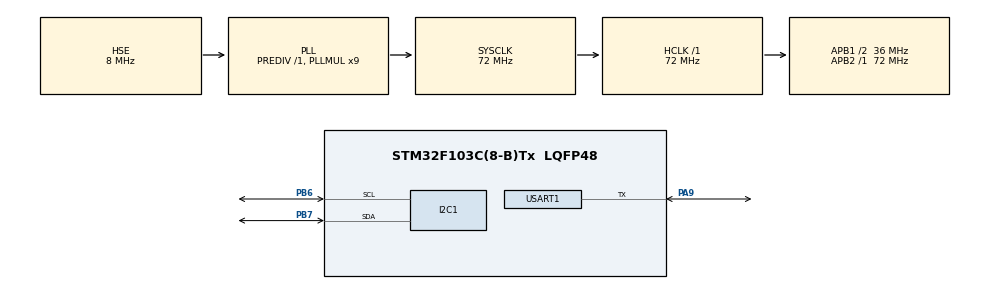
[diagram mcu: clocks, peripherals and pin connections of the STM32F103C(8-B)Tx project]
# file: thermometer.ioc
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Dma.Request0=USART1_RX
Dma.Request1=USART1_TX
Dma.USART1_RX.0.Direction=DMA_PERIPH_TO_MEMORY
Dma.USART1_RX.0.Instance=DMA1_Channel5
Dma.USART1_RX.0.MemDataAlignment=DMA_MDATAALIGN_BYTE
Dma.USART1_RX.0.MemInc=DMA_MINC_ENABLE
Dma.USART1_RX.0.Mode=DMA_NORMAL
Dma.USART1_RX.0.PeriphDataAlignment=DMA_PDATAALIGN_BYTE
Dma.USART1_RX.0.PeriphInc=DMA_PINC_DISABLE
Dma.USART1_RX.0.Priority=DMA_PRIORITY_LOW
Dma.USART1_TX.1.Direction=DMA_MEMORY_TO_PERIPH
Dma.USART1_TX.1.Instance=DMA1_Channel4
Dma.USART1_TX.1.MemDataAlignment=DMA_MDATAALIGN_BYTE
Dma.USART1_TX.1.MemInc=DMA_MINC_ENABLE
Dma.USART1_TX.1.Mode=DMA_NORMAL
Dma.USART1_TX.1.PeriphDataAlignment=DMA_PDATAALIGN_BYTE
Dma.USART1_TX.1.PeriphInc=DMA_PINC_DISABLE
Dma.USART1_TX.1.Priority=DMA_PRIORITY_LOW
Mcu.Family=STM32F1
Mcu.Name=STM32F103C(8-B)Tx
Mcu.Package=LQFP48
NVIC.DMA1_Channel4_IRQn=true\:15\:0\:true\:false\:true\:false\:true\:true
NVIC.DMA1_Channel5_IRQn=true\:15\:0\:true\:false\:true\:false\:true\:true
NVIC.PriorityGroup=NVIC_PRIORITYGROUP_4
NVIC.TIM2_IRQn=true\:14\:0\:true\:false\:true\:true\:true\:true
NVIC.USART1_IRQn=true\:0\:0\:false\:false\:true\:true\:true\:true
PA13.Mode=Serial_Wire
PA13.Signal=SYS_JTMS-SWDIO
PA14.Mode=Serial_Wire
PA14.Signal=SYS_JTCK-SWCLK
PA9.Mode=Half_duplex(single_wire_mode)
PA9.Signal=USART1_TX
PB6.Mode=I2C
PB6.Signal=I2C1_SCL
PB7.Mode=I2C
PB7.Signal=I2C1_SDA
PD0-OSC_IN.Mode=HSE-External-Oscillator
PD0-OSC_IN.Signal=RCC_OSC_IN
PD1-OSC_OUT.Mode=HSE-External-Oscillator
PD1-OSC_OUT.Signal=RCC_OSC_OUT
ProjectManager.HeapSize=0x200
ProjectManager.StackSize=0x400
ProjectManager.TargetToolchain=STM32CubeIDE
RCC.AHBFreq_Value=72000000
RCC.APB1CLKDivider=RCC_HCLK_DIV2
RCC.APB1Freq_Value=36000000
RCC.APB1TimFreq_Value=72000000
RCC.APB2Freq_Value=72000000
RCC.APB2TimFreq_Value=72000000
RCC.HCLKFreq_Value=72000000
RCC.PLLMUL=RCC_PLL_MUL9
RCC.PLLSourceVirtual=RCC_PLLSOURCE_HSE
RCC.SYSCLKFreq_VALUE=72000000
RCC.SYSCLKSource=RCC_SYSCLKSOURCE_PLLCLK
RCC.USBFreq_Value=72000000
TIM2.Period=49999
TIM2.Prescaler=2879
USART1.BaudRate=115200
USART1.VirtualMode=VM_ASYNC
VP_TIM2_VS_ClockSourceINT.Mode=Internal
VP_TIM2_VS_ClockSourceITR.Mode=TriggerSource_ITR0
board=custom

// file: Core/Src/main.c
/* USER CODE BEGIN Header */
/**
  ******************************************************************************
  * @file           : main.c
  * @brief          : Main program body
  ******************************************************************************
  * @attention
  *
  * Copyright (c) 2022 STMicroelectronics.
  * All rights reserved.
  *
  * This software is licensed under terms that can be found in the LICENSE file
  * in the root directory of this software component.
  * If no LICENSE file comes with this software, it is provided AS-IS.
  *
  ******************************************************************************
  */
/* USER CODE END Header */
#include "main.h"

 I2C_HandleTypeDef hi2c1;

TIM_HandleTypeDef htim2;

UART_HandleTypeDef huart1;
DMA_HandleTypeDef hdma_usart1_rx;
DMA_HandleTypeDef hdma_usart1_tx;

/* USER CODE BEGIN PV */
uint8_t scratchpad[9];
uint8_t rom[8];
uint8_t blink = 0;
uint8_t convert = 0xFF;
uint8_t need_statemachine_call = 0;
uint8_t need_command_call = 0;
/* USER CODE END PV */

void SystemClock_Config(void);
static void MX_GPIO_Init(void);
static void MX_I2C1_Init(void);
static void MX_DMA_Init(void);
static void MX_TIM2_Init(void);
static void MX_USART1_UART_Init(void);

/* USER CODE BEGIN 0 */

/*
void HAL_TIM_PeriodElapsedCallback(TIM_HandleTypeDef *htim)
{
//		HAL_ResumeTick();
        if(htim->Instance == TIM2) //check if the interrupt comes from TIM2
        {
        	ssd1306_SetCursor(10, 10);

        	float temp = DS18B20_TempFloat(scratchpad);

        	char buf[8];
        	sprintf(buf, "%2.1f", temp);
        	ssd1306_SetCursor(0, 20);
        	ssd1306_WriteString(buf, Font_7x10, White);
        	ssd1306_UpdateScreen();

        	if (OneWire_GetState() == 0) {
        		if (convert)
        			OneWire_Execute(0xcc,0,0x44,0); // start to Convert T
        		else
        			OneWire_Execute(0xcc,0,0xbe,scratchpad); // start to read configuration & result
        		convert = ~convert;
        	}
        }
//    	HAL_SuspendTick();
//   	HAL_PWR_EnterSLEEPMode(PWR_MAINREGULATOR_ON, PWR_SLEEPENTRY_WFI);
}
*/

void HAL_UART_TxCpltCallback(UART_HandleTypeDef *huart) {
		if (huart->Instance == USART1){
			OneWire_TxCpltCallback();
		}
}

void HAL_UART_RxCpltCallback(UART_HandleTypeDef *huart) {
		if (huart->Instance == USART1){
			OneWire_RxCpltCallback();
		}
}

void OneWire_OnErr() {
	ssd1306_SetCursor(0, 0);
	if(!blink)
		ssd1306_WriteString("ERROR", Font_7x10, White);
	else
		ssd1306_WriteString("     ", Font_7x10, White);
	blink = ~blink;
	ssd1306_UpdateScreen();
}

void OneWire_OnOk() {
	ssd1306_SetCursor(0, 0);
	if(!blink)
		ssd1306_WriteString("OK   ", Font_7x10, White);
	else
		ssd1306_WriteString("     ", Font_7x10, White);
	blink = ~blink;
	ssd1306_UpdateScreen();
}

/* USER CODE END 0 */

int main(void)
{

  /* MCU Configuration--------------------------------------------------------*/

  /* Reset of all peripherals, Initializes the Flash interface and the Systick. */
  HAL_Init();

  /* Configure the system clock */
  SystemClock_Config();

  /* Initialize all configured peripherals */
  MX_GPIO_Init();
  MX_I2C1_Init();
  MX_DMA_Init();
  MX_TIM2_Init();
  MX_USART1_UART_Init();
  /* USER CODE BEGIN 2 */

  HAL_UART_MspInit(&huart1);

  ssd1306_Init();
  OneWire_Init(&huart1);
  OneWire_SetCallback(OneWire_OnOk, OneWire_OnErr);

  HAL_TIM_Base_Start_IT(&htim2);

  /* USER CODE END 2 */

  /* Infinite loop */
  while (1)
  {

    /* USER CODE BEGIN 3 */
	if (need_statemachine_call) {
		StateMachine();
		need_statemachine_call = ~need_statemachine_call;
	}

	if (need_command_call) {
		float temp = DS18B20_TempFloat(scratchpad);

		char buf[8];
		sprintf(buf, "%2.1f", temp);
		ssd1306_SetCursor(0, 20);
		ssd1306_WriteString(buf, Font_7x10, White);
		//ssd1306_UpdateScreen();

		if (OneWire_GetState() == 0) {
			if (convert)
				OneWire_Execute(0xcc,0,0x44,rom); // start to Convert T
			else
				OneWire_Execute(0xcc,0,0xbe,scratchpad); // start to read configuration & result
			convert = ~convert;
		}
		need_command_call = 0;
	}
	//HAL_SuspendTick();
	//HAL_PWR_EnterSLEEPMode(PWR_MAINREGULATOR_ON, PWR_SLEEPENTRY_WFI);
  }
  /* USER CODE END 3 */
}

void SystemClock_Config(void)
{
  RCC_OscInitTypeDef RCC_OscInitStruct = {0};
  RCC_ClkInitTypeDef RCC_ClkInitStruct = {0};

  /** Initializes the RCC Oscillators according to the specified parameters
  * in the RCC_OscInitTypeDef structure.
  */
  RCC_OscInitStruct.OscillatorType = RCC_OSCILLATORTYPE_HSE;
  RCC_OscInitStruct.HSEState = RCC_HSE_ON;
  RCC_OscInitStruct.HSEPredivValue = RCC_HSE_PREDIV_DIV1;
  RCC_OscInitStruct.HSIState = RCC_HSI_ON;
  RCC_OscInitStruct.PLL.PLLState = RCC_PLL_ON;
  RCC_OscInitStruct.PLL.PLLSource = RCC_PLLSOURCE_HSE;
  RCC_OscInitStruct.PLL.PLLMUL = RCC_PLL_MUL9;
  if (HAL_RCC_OscConfig(&RCC_OscInitStruct) != HAL_OK)
  {
    Error_Handler();
  }

  /** Initializes the CPU, AHB and APB buses clocks
  */
  RCC_ClkInitStruct.ClockType = RCC_CLOCKTYPE_HCLK|RCC_CLOCKTYPE_SYSCLK
                              |RCC_CLOCKTYPE_PCLK1|RCC_CLOCKTYPE_PCLK2;
  RCC_ClkInitStruct.SYSCLKSource = RCC_SYSCLKSOURCE_PLLCLK;
  RCC_ClkInitStruct.AHBCLKDivider = RCC_SYSCLK_DIV1;
  RCC_ClkInitStruct.APB1CLKDivider = RCC_HCLK_DIV2;
  RCC_ClkInitStruct.APB2CLKDivider = RCC_HCLK_DIV1;

  if (HAL_RCC_ClockConfig(&RCC_ClkInitStruct, FLASH_LATENCY_2) != HAL_OK)
  {
    Error_Handler();
  }
}

static void MX_I2C1_Init(void)
{

  hi2c1.Instance = I2C1;
  hi2c1.Init.ClockSpeed = 100000;
  hi2c1.Init.DutyCycle = I2C_DUTYCYCLE_2;
  hi2c1.Init.OwnAddress1 = 0;
  hi2c1.Init.AddressingMode = I2C_ADDRESSINGMODE_7BIT;
  hi2c1.Init.DualAddressMode = I2C_DUALADDRESS_DISABLE;
  hi2c1.Init.OwnAddress2 = 0;
  hi2c1.Init.GeneralCallMode = I2C_GENERALCALL_DISABLE;
  hi2c1.Init.NoStretchMode = I2C_NOSTRETCH_DISABLE;
  if (HAL_I2C_Init(&hi2c1) != HAL_OK)
  {
    Error_Handler();
  }

}

static void MX_TIM2_Init(void)
{

  TIM_ClockConfigTypeDef sClockSourceConfig = {0};
  TIM_SlaveConfigTypeDef sSlaveConfig = {0};
  TIM_MasterConfigTypeDef sMasterConfig = {0};

  htim2.Instance = TIM2;
  htim2.Init.Prescaler = 2879;
  htim2.Init.CounterMode = TIM_COUNTERMODE_UP;
  htim2.Init.Period = 49999;
  htim2.Init.ClockDivision = TIM_CLOCKDIVISION_DIV1;
  htim2.Init.AutoReloadPreload = TIM_AUTORELOAD_PRELOAD_DISABLE;
  if (HAL_TIM_Base_Init(&htim2) != HAL_OK)
  {
    Error_Handler();
  }
  sClockSourceConfig.ClockSource = TIM_CLOCKSOURCE_INTERNAL;
  if (HAL_TIM_ConfigClockSource(&htim2, &sClockSourceConfig) != HAL_OK)
  {
    Error_Handler();
  }
  sSlaveConfig.SlaveMode = TIM_SLAVEMODE_DISABLE;
  sSlaveConfig.InputTrigger = TIM_TS_ITR0;
  if (HAL_TIM_SlaveConfigSynchro(&htim2, &sSlaveConfig) != HAL_OK)
  {
    Error_Handler();
  }
  sMasterConfig.MasterOutputTrigger = TIM_TRGO_RESET;
  sMasterConfig.MasterSlaveMode = TIM_MASTERSLAVEMODE_DISABLE;
  if (HAL_TIMEx_MasterConfigSynchronization(&htim2, &sMasterConfig) != HAL_OK)
  {
    Error_Handler();
  }

}

static void MX_USART1_UART_Init(void)
{

  huart1.Instance = USART1;
  huart1.Init.BaudRate = 115200;
  huart1.Init.WordLength = UART_WORDLENGTH_8B;
  huart1.Init.StopBits = UART_STOPBITS_1;
  huart1.Init.Parity = UART_PARITY_NONE;
  huart1.Init.Mode = UART_MODE_TX_RX;
  huart1.Init.HwFlowCtl = UART_HWCONTROL_NONE;
  huart1.Init.OverSampling = UART_OVERSAMPLING_16;
  if (HAL_HalfDuplex_Init(&huart1) != HAL_OK)
  {
    Error_Handler();
  }

}

static void MX_DMA_Init(void)
{

  /* DMA controller clock enable */
  __HAL_RCC_DMA1_CLK_ENABLE();

  /* DMA interrupt init */
  /* DMA1_Channel4_IRQn interrupt configuration */
  HAL_NVIC_SetPriority(DMA1_Channel4_IRQn, 15, 0);
  HAL_NVIC_EnableIRQ(DMA1_Channel4_IRQn);
  /* DMA1_Channel5_IRQn interrupt configuration */
  HAL_NVIC_SetPriority(DMA1_Channel5_IRQn, 15, 0);
  HAL_NVIC_EnableIRQ(DMA1_Channel5_IRQn);

}

static void MX_GPIO_Init(void)
{

  /* GPIO Ports Clock Enable */
  __HAL_RCC_GPIOD_CLK_ENABLE();
  __HAL_RCC_GPIOA_CLK_ENABLE();
  __HAL_RCC_GPIOB_CLK_ENABLE();

}

void Error_Handler(void)
{
  __disable_irq();
  while (1)
  {
  }
}
